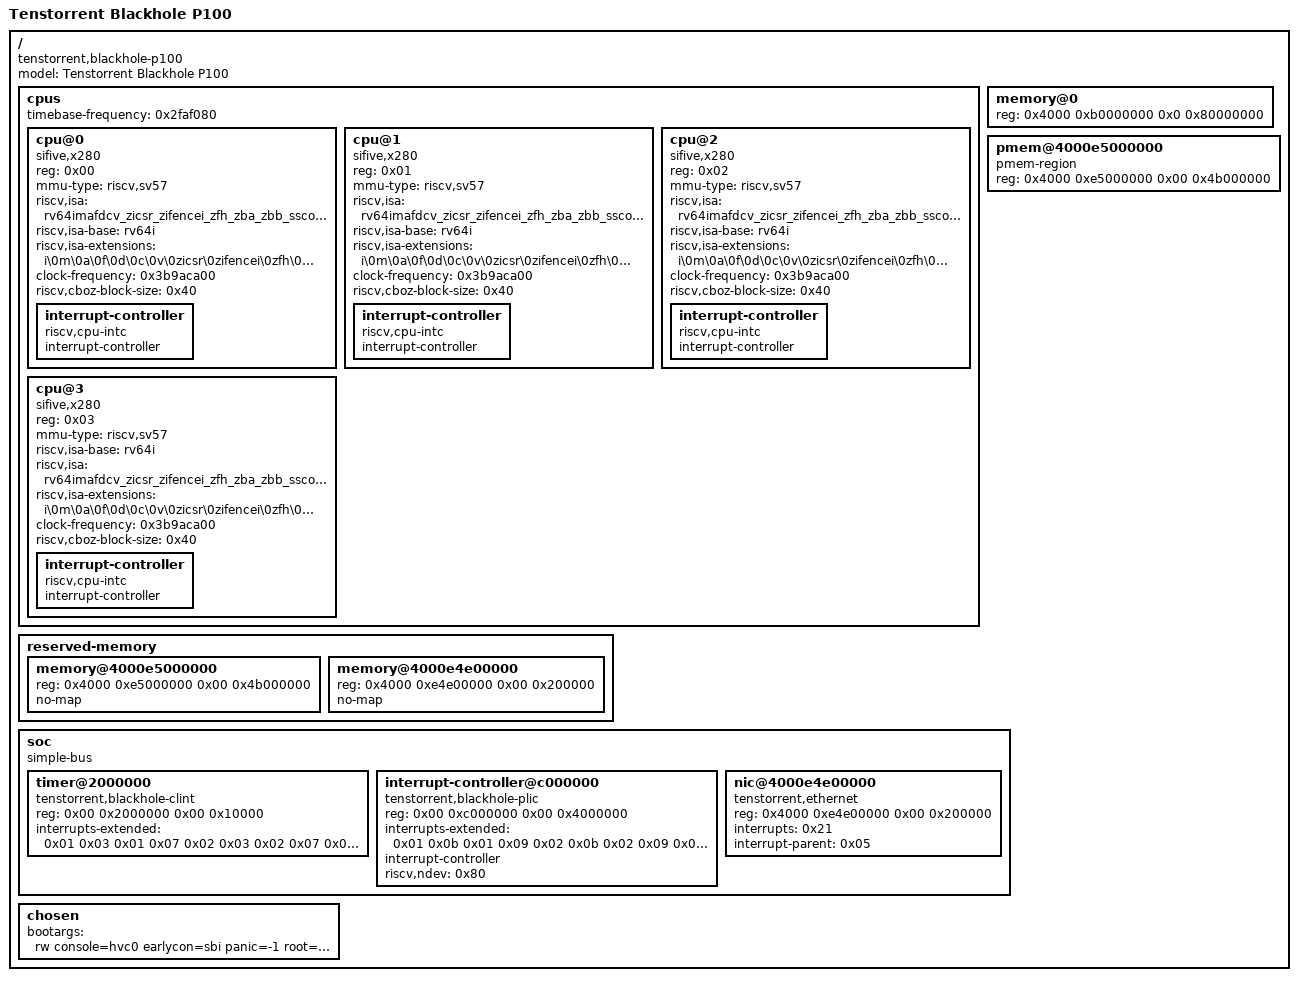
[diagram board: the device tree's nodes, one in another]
/dts-v1/;
// SPDX-FileCopyrightText: © 2025 Tenstorrent AI ULC
// SPDX-License-Identifier: (GPL-2.0 OR MIT)

/ {
	compatible = "tenstorrent,blackhole-p100\0tenstorrent,blackhole";
	#address-cells = <0x02>;
	#size-cells = <0x02>;
	model = "Tenstorrent Blackhole P100";

	cpus {
		#address-cells = <0x01>;
		#size-cells = <0x00>;
		timebase-frequency = <0x2faf080>;

		cpu@0 {
			compatible = "sifive,x280\0sifive,rocket0\0riscv";
			device_type = "cpu";
			reg = <0x00>;
			mmu-type = "riscv,sv57";
			riscv,isa = "rv64imafdcv_zicsr_zifencei_zfh_zba_zbb_sscofpmf";
			riscv,isa-base = "rv64i";
			riscv,isa-extensions = "i\0m\0a\0f\0d\0c\0v\0zicsr\0zifencei\0zfh\0zba\0zbb\0sscofpmf";
			clock-frequency = <0x3b9aca00>;
			riscv,cboz-block-size = <0x40>;
			status = "okay";

			interrupt-controller {
				compatible = "riscv,cpu-intc";
				#interrupt-cells = <0x01>;
				interrupt-controller;
				phandle = <0x01>;
			};
		};

		cpu@1 {
			compatible = "sifive,x280\0sifive,rocket0\0riscv";
			device_type = "cpu";
			reg = <0x01>;
			mmu-type = "riscv,sv57";
			riscv,isa = "rv64imafdcv_zicsr_zifencei_zfh_zba_zbb_sscofpmf";
			riscv,isa-base = "rv64i";
			riscv,isa-extensions = "i\0m\0a\0f\0d\0c\0v\0zicsr\0zifencei\0zfh\0zba\0zbb\0sscofpmf";
			clock-frequency = <0x3b9aca00>;
			riscv,cboz-block-size = <0x40>;
			status = "okay";

			interrupt-controller {
				compatible = "riscv,cpu-intc";
				#interrupt-cells = <0x01>;
				interrupt-controller;
				phandle = <0x02>;
			};
		};

		cpu@2 {
			compatible = "sifive,x280\0sifive,rocket0\0riscv";
			device_type = "cpu";
			reg = <0x02>;
			mmu-type = "riscv,sv57";
			riscv,isa = "rv64imafdcv_zicsr_zifencei_zfh_zba_zbb_sscofpmf";
			riscv,isa-base = "rv64i";
			riscv,isa-extensions = "i\0m\0a\0f\0d\0c\0v\0zicsr\0zifencei\0zfh\0zba\0zbb\0sscofpmf";
			clock-frequency = <0x3b9aca00>;
			riscv,cboz-block-size = <0x40>;
			status = "okay";

			interrupt-controller {
				compatible = "riscv,cpu-intc";
				#interrupt-cells = <0x01>;
				interrupt-controller;
				phandle = <0x03>;
			};
		};

		cpu@3 {
			compatible = "sifive,x280\0sifive,rocket0\0riscv";
			device_type = "cpu";
			reg = <0x03>;
			mmu-type = "riscv,sv57";
			riscv,isa-base = "rv64i";
			riscv,isa = "rv64imafdcv_zicsr_zifencei_zfh_zba_zbb_sscofpmf";
			riscv,isa-extensions = "i\0m\0a\0f\0d\0c\0v\0zicsr\0zifencei\0zfh\0zba\0zbb\0sscofpmf";
			clock-frequency = <0x3b9aca00>;
			riscv,cboz-block-size = <0x40>;
			status = "okay";

			interrupt-controller {
				compatible = "riscv,cpu-intc";
				#interrupt-cells = <0x01>;
				interrupt-controller;
				phandle = <0x04>;
			};
		};
	};

	memory@0 {
		device_type = "memory";
		reg = <0x4000 0xb0000000 0x0 0x80000000>;
	};

	reserved-memory {
		#address-cells = <0x02>;
		#size-cells = <0x02>;
		ranges;

		memory@4000e5000000 {
			reg = <0x4000 0xe5000000 0x00 0x4b000000>;
			no-map;
		};

		memory@4000e4e00000 {
			reg = <0x4000 0xe4e00000 0x00 0x200000>;
			no-map;
		};
	};

	pmem@4000e5000000 {
		compatible = "pmem-region";
		reg = <0x4000 0xe5000000 0x00 0x4b000000>;
	};

	soc {
		#address-cells = <0x02>;
		#size-cells = <0x02>;
		compatible = "simple-bus";
		ranges;

		timer@2000000 {
			compatible = "tenstorrent,blackhole-clint\0sifive,clint0";
			reg = <0x00 0x2000000 0x00 0x10000>;
			interrupts-extended = <0x01 0x03 0x01 0x07 0x02 0x03 0x02 0x07 0x03 0x03 0x03 0x07 0x04 0x03 0x04 0x07>;
		};

		interrupt-controller@c000000 {
			compatible = "tenstorrent,blackhole-plic\0sifive,plic-1.0.0";
			reg = <0x00 0xc000000 0x00 0x4000000>;
			interrupts-extended = <0x01 0x0b 0x01 0x09 0x02 0x0b 0x02 0x09 0x03 0x0b 0x03 0x09 0x04 0x0b 0x04 0x09>;
			interrupt-controller;
			#interrupt-cells = <0x01>;
			#address-cells = <0x00>;
			riscv,ndev = <0x80>;
			phandle = <0x05>;
		};

		nic@4000e4e00000 {
			compatible = "tenstorrent,ethernet";
			reg = <0x4000 0xe4e00000 0x00 0x200000>;
			interrupts = <0x21>;
			interrupt-parent = <0x05>;
		};
	};

	chosen {
		bootargs = "rw console=hvc0 earlycon=sbi panic=-1 root=/dev/pmem0";
	};
};
